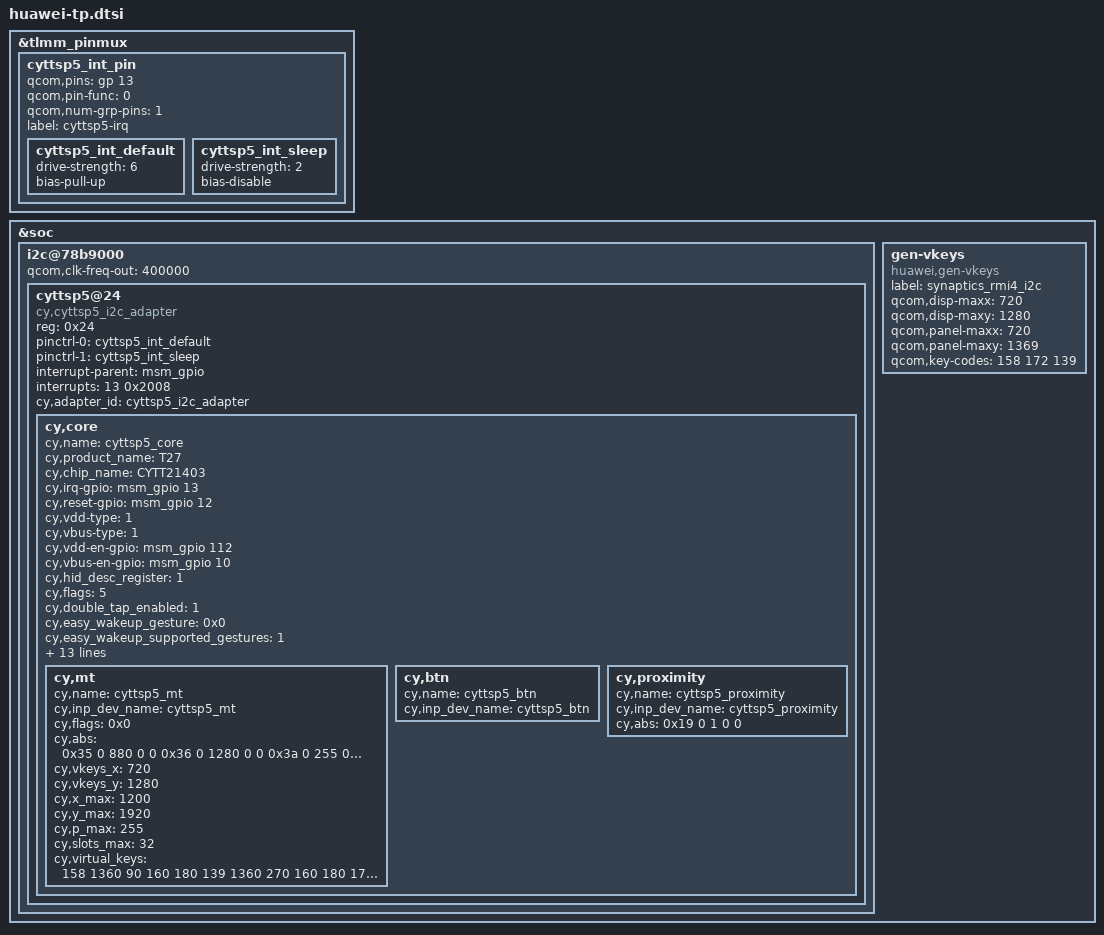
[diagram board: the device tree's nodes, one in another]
/* < DTS2015071605523 guotiecheng 20150716 begin */
/*Add synaptics new driver "Synaptics DSX I2C V2.0"*/
/* Open holster flag */
/*Change i2c frepuence from 100kHZ to 400kHZ*/
/*Open fast-relax config for better gesture performance*/
&tlmm_pinmux {

	cyttsp5_int_pin {
		qcom,pins = <&gp 13>;
		qcom,pin-func = <0>;
		qcom,num-grp-pins = <1>;
		label = "cyttsp5-irq";
		cyttsp5_int_default: cyttsp5_int_default {
			drive-strength = <6>;
			bias-pull-up;
		};
		cyttsp5_int_sleep: cyttsp5_int_sleep {
			drive-strength = <2>;
			bias-disable;
		};
	};
};
&soc {
	i2c@78b9000 { /* BLSP1 QUP5 */
		status = "ok";
		#address-cells = <1>;
		#size-cells = <0>;
		qcom,clk-freq-out = <400000>;
		
		cyttsp5@24 {
			compatible = "cy,cyttsp5_i2c_adapter";
			/*DTS2015093003552 pwx271249 20150930 begin */
			reg = <0x24>;
			/*DTS2015093003552 pwx271249 20150930 end*/
			pinctrl-names = "int_default","int_sleep";
			pinctrl-0 = <&cyttsp5_int_default>;
			pinctrl-1 = <&cyttsp5_int_sleep>;
			interrupt-parent = <&msm_gpio>;
			interrupts = <13 0x2008>;
			cy,adapter_id = "cyttsp5_i2c_adapter";
			/*vdd-supply = <&pm8916_l17>;*/
			/*< DTS2015112100416 pwx271249 20151123 begin >*/
			/*vcc_i2c-supply = <&pm8916_l16>;*/
			/*< DTS2015112100416 pwx271249 20151123 end >*/
			/* Some of qcom's param will not be replaced by huawei in dtb, */
			/* just ignore them:such as "pinctrl-names","pinctrl-0","pinctrl-1", */
			/* "cyttsp5,display-coords","cyttsp5,panel-coords","cyttsp5,i2c-pull-up", */
			/* "cyttsp5,power-down","cyttsp5,disable-gpios"*/
			/* < DTS2015032800844 caowei 20150319 begin */
			/* cy,vdd = "vdd"; */
			/* cy,vbus = "vcc_i2c"; */
			/* DTS2015032800844 caowei 20150319 end > */
			cy,core {
				cy,name = "cyttsp5_core";
				/* < DTS2014112404549 caowei 20141128 begin */
				/*DTS2015093003552 pwx271249 20150930 begin*/
				cy,product_name = "T27";
				/*DTS2015093003552 pwx271249 20150930 end*/
				cy,chip_name = "CYTT21403";
				/* DTS2014112404549 caowei 20141128 end > */

				cy,irq-gpio = <&msm_gpio 13 0x2008>;
				cy,reset-gpio = <&msm_gpio 12 0x0>;
				/* < DTS2015032800844 caowei 20150319 begin */
				cy,vdd-type = <1>;	/* 0:null, 1:gpio, 2:pmu*/
				/*< DTS2015112100416 pwx271249 20151123 begin >*/
				cy,vbus-type = <1>;	/* 0:null, 1:gpio, 2:pmu*/
				/*< DTS2015112100416 pwx271249 20151123 end >*/
				
				/*cy,vdd = "vdd";*/
				cy,vdd-en-gpio = <&msm_gpio 112 0x0>; 
				/*< DTS2015112100416 pwx271249 20151123 begin >*/
				/*cy,vbus = "vcc_i2c";*/
				cy,vbus-en-gpio = <&msm_gpio 10 0x0>;
				/*< DTS2015112100416 pwx271249 20151123 end >*/
				/*cy,fw_upgrade_start_ver = <4>;*/
				/* DTS2015032800844 caowei 20150319 end > */
				cy,hid_desc_register = <1>;
				/* CY_CORE_FLAG_WAKE_ON_GESTURE | CY_CORE_FLAG_RESTORE_PARAMETERS */
				cy,flags = <5>;
				/* CY_CORE_EWG_NONE */

				cy,double_tap_enabled = <1>;
				cy,easy_wakeup_gesture = <0x0>;
				cy,easy_wakeup_supported_gestures = <1>;
				/* Double-tap-zone defined by huawei */
				/* Shielded area is:1cm left,1cm right,1cm up,1cm down */
				cy,dtz_x0 = <125>;
				cy,dtz_y0 = <130>;
				cy,dtz_x1 = <1075>;
				cy,dtz_y1 = <1790>;
				/*Defination of report key value  for different gestures*/
                                cy,easy_wakeup_gesture_keys =
                                <       59 /*0.Double tap:KEY_F1*/
                                        60 /*1.Single finger slide from left to right*/
                                        61 /*2.Single finger slide from right to left:KEY_F3*/
                                        62 /*3.Single finger slide from top to bottom*/
                                        63 /*4.Single finger slide from bottom to top:KEY_F5*/
                                        64 /*5.Single finger slide circle clockwise*/
                                        65 /*6.Single finger slide circle counter-clockwise*/
                                        66 /*7.Single finger write letter c*/
                                        67 /*8.Single finger write letter e:KEY_F9*/
                                        68 /*9.Single finger write letter m*/
                                        87 /*10.Single finger write letter w:KEY_F11*/
                                        88 /*11.Palm off screen*/
                                >;

				/* DTS2015012302601 songrongyuan 20150123 end >*/
				cy,btn_keys = <139	/* KEY_MENU */
					       158>;	/* KEY_BACK */
				cy,btn_keys-tag = <0>;
				/* < DTS2015032704844  dingjingfeng 20150401 begin */
				cy,glove_support = <1>;
				/* DTS2015032704844  dingjingfeng 20150401 end >*/
				/* < DTS2015041002514  dingjingfeng 20150415 begin */
				cy,holster_support = <1>;
				/* DTS2015041002514  dingjingfeng 20150415 end > */
				cy,mmi_test_support = <1>;
				cy,new_fpc_flag = <1>;
				cy,input_register_early = <1>;
				cy,mt {
					cy,name = "cyttsp5_mt";

					cy,inp_dev_name = "cyttsp5_mt";
					/*DTS2015093003552 pwx271249 20150930 begin*/
					cy,flags = <0x0>;/* CY_MT_FLAG_FLIP | CY_MT_FLAG_INV_X | CY_MT_FLAG_INV_Y */
					/*DTS2015093003552 pwx271249 20150930 end*/
					cy,abs =
						/* ABS_MT_POSITION_X, CY_ABS_MIN_X, CY_ABS_MAX_X, 0, 0 */
						<0x35 0 880 0 0
						/* ABS_MT_POSITION_Y, CY_ABS_MIN_Y, CY_ABS_MAX_Y, 0, 0 */
						0x36 0 1280 0 0
						/* ABS_MT_PRESSURE, CY_ABS_MIN_P, CY_ABS_MAX_P, 0, 0 */
						0x3a 0 255 0 0
						/* CY_IGNORE_VALUE, CY_ABS_MIN_W, CY_ABS_MAX_W, 0, 0 */
						0xffff 0 255 0 0
						/* ABS_MT_TRACKING_ID, CY_ABS_MIN_T, CY_ABS_MAX_T, 0, 0 */
						0x39 0 15 0 0
						/* ABS_MT_TOUCH_MAJOR, 0, 255, 0, 0 */
						0x30 0 255 0 0
						/* ABS_MT_TOUCH_MINOR, 0, 255, 0, 0 */
						0x31 0 255 0 0
						/* ABS_MT_ORIENTATION, -127, 127, 0, 0 */
						0x34 0xffffff81 127 0 0
						/* < DTS2015022701623  dingjingfeng 20150320 begin */
						//delete lines
						/* DTS2015022701623  dingjingfeng 20150320 end > */
						/* ABS_DISTANCE, 0, 255, 0, 0 */
						0x19 0 255 0 0>;

					cy,vkeys_x = <720>;
					cy,vkeys_y = <1280>;
					cy,x_max = <1200>;
					cy,y_max = <1920>;
					cy,p_max = <255>;
					cy,slots_max = <32>;

					cy,virtual_keys = /* KeyCode CenterX CenterY Width Height */
						/* KEY_BACK */
						<158 1360 90 160 180
						/* KEY_MENU */
						139 1360 270 160 180
						/* KEY_HOMEPAGE */
						172 1360 450 160 180
						/* KEY SEARCH */
						217 1360 630 160 180>;
				};

				cy,btn {
					cy,name = "cyttsp5_btn";

					cy,inp_dev_name = "cyttsp5_btn";
				};

				cy,proximity {
					cy,name = "cyttsp5_proximity";

					cy,inp_dev_name = "cyttsp5_proximity";
					cy,abs =
						/* ABS_DISTANCE, CY_PROXIMITY_MIN_VAL, CY_PROXIMITY_MAX_VAL, 0, 0 */
						<0x19 0 1 0 0>;
				};
			};
		};
	};
	
	/*To disable gen-vkeys.c probe,avoid generate kobject*/
	gen-vkeys {
		compatible = "huawei,gen-vkeys";
		label = "synaptics_rmi4_i2c";
		qcom,disp-maxx = <720>;
		qcom,disp-maxy = <1280>;
		qcom,panel-maxx = <720>;
		qcom,panel-maxy = <1369>;
		qcom,key-codes = <158 172 139>;
	};
};
/* < DTS2015032002361 huangli 20150401 end > */
/* DTS2014090505039 zhujie 20140905 end > */
/* DTS2014122210216 songrongyuan 20141222 end > */
